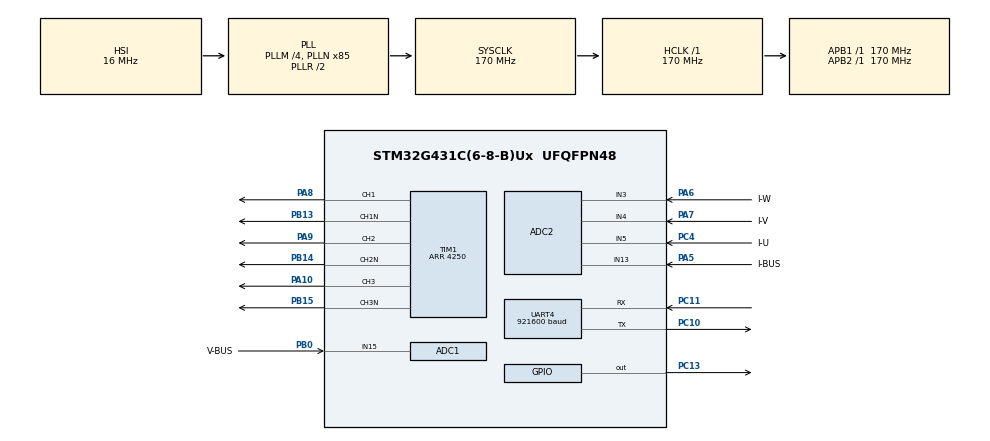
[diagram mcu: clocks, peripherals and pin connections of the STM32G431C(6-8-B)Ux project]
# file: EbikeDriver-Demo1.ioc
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ADC1.Channel-0\#ChannelRegularConversion=ADC_CHANNEL_15
ADC1.ContinuousConvMode=DISABLE
ADC1.DMAContinuousRequests=ENABLE
ADC1.EnableInjectedConversion=DISABLE
ADC1.ExternalTrigConv=ADC_EXTERNALTRIG_T1_TRGO2
ADC1.NbrOfConversionFlag=1
ADC1.OffsetNumber-0\#ChannelRegularConversion=ADC_OFFSET_NONE
ADC1.Overrun=ADC_OVR_DATA_PRESERVED
ADC1.Rank-0\#ChannelRegularConversion=1
ADC1.SamplingTime-0\#ChannelRegularConversion=ADC_SAMPLETIME_12CYCLES_5
ADC1.master=1
ADC2.ClockPrescaler=ADC_CLOCK_SYNC_PCLK_DIV4
ADC2.EnableInjectedConversion=ENABLE
ADC2.EnableRegularConversion=DISABLE
ADC2.ExternalTrigInjecConv=ADC_EXTERNALTRIGINJEC_T1_CC4
ADC2.InjNumberOfConversion=4
ADC2.InjectedChannel-1\#ChannelInjectedConversion=ADC_CHANNEL_13
ADC2.InjectedChannel-2\#ChannelInjectedConversion=ADC_CHANNEL_5
ADC2.InjectedChannel-3\#ChannelInjectedConversion=ADC_CHANNEL_4
ADC2.InjectedChannel-5\#ChannelInjectedConversion=ADC_CHANNEL_3
ADC2.InjectedOffsetNumber-1\#ChannelInjectedConversion=ADC_OFFSET_NONE
ADC2.InjectedOffsetNumber-2\#ChannelInjectedConversion=ADC_OFFSET_NONE
ADC2.InjectedOffsetNumber-3\#ChannelInjectedConversion=ADC_OFFSET_NONE
ADC2.InjectedOffsetNumber-5\#ChannelInjectedConversion=ADC_OFFSET_NONE
ADC2.InjectedRank-1\#ChannelInjectedConversion=1
ADC2.InjectedRank-2\#ChannelInjectedConversion=2
ADC2.InjectedRank-3\#ChannelInjectedConversion=3
ADC2.InjectedRank-5\#ChannelInjectedConversion=4
ADC2.InjectedSamplingTime-1\#ChannelInjectedConversion=ADC_SAMPLETIME_12CYCLES_5
ADC2.InjectedSamplingTime-2\#ChannelInjectedConversion=ADC_SAMPLETIME_12CYCLES_5
ADC2.InjectedSamplingTime-3\#ChannelInjectedConversion=ADC_SAMPLETIME_12CYCLES_5
ADC2.InjectedSamplingTime-5\#ChannelInjectedConversion=ADC_SAMPLETIME_12CYCLES_5
ADC2.Rank1_Channel=ADC_CHANNEL_13
ADC2.Rank2_Channel=ADC_CHANNEL_5
ADC2.Rank3_Channel=ADC_CHANNEL_4
ADC2.Rank4_Channel=ADC_CHANNEL_3
Dma.ADC1.1.Direction=DMA_PERIPH_TO_MEMORY
Dma.ADC1.1.EventEnable=DISABLE
Dma.ADC1.1.Instance=DMA1_Channel2
Dma.ADC1.1.MemDataAlignment=DMA_MDATAALIGN_HALFWORD
Dma.ADC1.1.MemInc=DMA_MINC_ENABLE
Dma.ADC1.1.Mode=DMA_CIRCULAR
Dma.ADC1.1.PeriphDataAlignment=DMA_PDATAALIGN_HALFWORD
Dma.ADC1.1.PeriphInc=DMA_PINC_DISABLE
Dma.ADC1.1.Polarity=HAL_DMAMUX_REQ_GEN_RISING
Dma.ADC1.1.Priority=DMA_PRIORITY_LOW
Dma.ADC1.1.RequestNumber=1
Dma.ADC1.1.SignalID=NONE
Dma.ADC1.1.SyncEnable=DISABLE
Dma.ADC1.1.SyncPolarity=HAL_DMAMUX_SYNC_NO_EVENT
Dma.ADC1.1.SyncRequestNumber=1
Dma.ADC1.1.SyncSignalID=NONE
Dma.Request0=UART4_TX
Dma.Request1=ADC1
Dma.UART4_TX.0.Direction=DMA_MEMORY_TO_PERIPH
Dma.UART4_TX.0.EventEnable=DISABLE
Dma.UART4_TX.0.Instance=DMA1_Channel1
Dma.UART4_TX.0.MemDataAlignment=DMA_MDATAALIGN_BYTE
Dma.UART4_TX.0.MemInc=DMA_MINC_ENABLE
Dma.UART4_TX.0.Mode=DMA_NORMAL
Dma.UART4_TX.0.PeriphDataAlignment=DMA_PDATAALIGN_BYTE
Dma.UART4_TX.0.PeriphInc=DMA_PINC_DISABLE
Dma.UART4_TX.0.Polarity=HAL_DMAMUX_REQ_GEN_RISING
Dma.UART4_TX.0.Priority=DMA_PRIORITY_LOW
Dma.UART4_TX.0.RequestNumber=1
Dma.UART4_TX.0.SignalID=NONE
Dma.UART4_TX.0.SyncEnable=DISABLE
Dma.UART4_TX.0.SyncPolarity=HAL_DMAMUX_SYNC_NO_EVENT
Dma.UART4_TX.0.SyncRequestNumber=1
Dma.UART4_TX.0.SyncSignalID=NONE
Mcu.Family=STM32G4
Mcu.Name=STM32G431C(6-8-B)Ux
Mcu.Package=UFQFPN48
NVIC.ADC1_2_IRQn=true\:0\:0\:false\:false\:true\:true\:true\:true
NVIC.DMA1_Channel1_IRQn=true\:1\:0\:true\:false\:true\:false\:true\:true
NVIC.DMA1_Channel2_IRQn=true\:2\:0\:true\:false\:true\:false\:true\:true
NVIC.PriorityGroup=NVIC_PRIORITYGROUP_4
NVIC.UART4_IRQn=true\:2\:0\:true\:false\:true\:true\:true\:true
PA10.Signal=S_TIM1_CH3
PA13.Mode=Serial_Wire
PA13.Signal=SYS_JTMS-SWDIO
PA14.Mode=Serial_Wire
PA14.Signal=SYS_JTCK-SWCLK
PA5.GPIO_Label=I-BUS
PA5.Mode=IN13-Single-Ended
PA5.Signal=ADC2_IN13
PA6.GPIO_Label=I-W
PA6.Mode=IN3-Single-Ended
PA6.Signal=ADC2_IN3
PA7.GPIO_Label=I-V
PA7.Mode=IN4-Single-Ended
PA7.Signal=ADC2_IN4
PA8.Signal=S_TIM1_CH1
PA9.Signal=S_TIM1_CH2
PB0.GPIO_Label=V-BUS
PB0.Mode=IN15-Single-Ended
PB0.Signal=ADC1_IN15
PB13.Mode=PWM Generation1 CH1 CH1N
PB13.Signal=TIM1_CH1N
PB14.Mode=PWM Generation2 CH2 CH2N
PB14.Signal=TIM1_CH2N
PB15.Mode=PWM Generation3 CH3 CH3N
PB15.Signal=TIM1_CH3N
PC10.Mode=Asynchronous
PC10.Signal=UART4_TX
PC11.Mode=Asynchronous
PC11.Signal=UART4_RX
PC13.Signal=GPIO_Output
PC4.GPIO_Label=I-U
PC4.Mode=IN5-Single-Ended
PC4.Signal=ADC2_IN5
PF0-OSC_IN.Mode=HSE-External-Oscillator
PF0-OSC_IN.Signal=RCC_OSC_IN
PF1-OSC_OUT.Mode=HSE-External-Oscillator
PF1-OSC_OUT.Signal=RCC_OSC_OUT
ProjectManager.HeapSize=0x200
ProjectManager.StackSize=0x400
ProjectManager.TargetToolchain=CMake
RCC.ADC12Freq_Value=170000000
RCC.AHBFreq_Value=170000000
RCC.APB1Freq_Value=170000000
RCC.APB1TimFreq_Value=170000000
RCC.APB2Freq_Value=170000000
RCC.APB2TimFreq_Value=170000000
RCC.CortexFreq_Value=170000000
RCC.EXTERNAL_CLOCK_VALUE=12288000
RCC.HCLKFreq_Value=170000000
RCC.HSE_VALUE=8000000
RCC.HSI48_VALUE=48000000
RCC.HSI_VALUE=16000000
RCC.LSE_VALUE=32768
RCC.PLLM=RCC_PLLM_DIV4
RCC.PLLN=85
RCC.SYSCLKFreq_VALUE=170000000
RCC.SYSCLKSource=RCC_SYSCLKSOURCE_PLLCLK
RCC.USBFreq_Value=170000000
RCC.VCOOutputFreq_Value=340000000
SH.S_TIM1_CH1.0=TIM1_CH1,PWM Generation1 CH1 CH1N
SH.S_TIM1_CH2.0=TIM1_CH2,PWM Generation2 CH2 CH2N
SH.S_TIM1_CH3.0=TIM1_CH3,PWM Generation3 CH3 CH3N
TIM1.Channel-PWM\ Generation1\ CH1\ CH1N=TIM_CHANNEL_1
TIM1.Channel-PWM\ Generation2\ CH2\ CH2N=TIM_CHANNEL_2
TIM1.Channel-PWM\ Generation3\ CH3\ CH3N=TIM_CHANNEL_3
TIM1.Channel-PWM\ Generation4\ No\ Output=TIM_CHANNEL_4
TIM1.CounterMode=TIM_COUNTERMODE_CENTERALIGNED1
TIM1.DeadTime=32
TIM1.OCNPolarity_1=TIM_OCNPOLARITY_LOW
TIM1.OCNPolarity_2=TIM_OCNPOLARITY_LOW
TIM1.OCNPolarity_3=TIM_OCNPOLARITY_LOW
TIM1.OCPolarity_1=TIM_OCPOLARITY_LOW
TIM1.OCPolarity_2=TIM_OCPOLARITY_LOW
TIM1.OCPolarity_3=TIM_OCPOLARITY_LOW
TIM1.PeriodNoDither=4250
TIM1.TIM_MasterOutputTrigger=TIM_TRGO_OC4REF
TIM1.TIM_MasterOutputTrigger2=TIM_TRGO2_OC4REF
UART4.BaudRate=921600
UART4.Mode=MODE_TX
VP_SYS_VS_DBSignals.Mode=DisableDeadBatterySignals
VP_TIM1_VS_no_output4.Mode=PWM Generation4 No Output
board=custom

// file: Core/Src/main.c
/* USER CODE BEGIN Header */
/**
  ******************************************************************************
  * @file           : main.c
  * @brief          : Main program body
  ******************************************************************************
  * @attention
  *
  * Copyright (c) 2026 STMicroelectronics.
  * All rights reserved.
  *
  * This software is licensed under terms that can be found in the LICENSE file
  * in the root directory of this software component.
  * If no LICENSE file comes with this software, it is provided AS-IS.
  *
  ******************************************************************************
  */
/* USER CODE END Header */
#include "main.h"

ADC_HandleTypeDef hadc1;
ADC_HandleTypeDef hadc2;
DMA_HandleTypeDef hdma_adc1;

TIM_HandleTypeDef htim1;

UART_HandleTypeDef huart4;
DMA_HandleTypeDef hdma_uart4_tx;

void SystemClock_Config(void);
static void MX_GPIO_Init(void);
static void MX_DMA_Init(void);
static void MX_ADC2_Init(void);
static void MX_TIM1_Init(void);
static void MX_UART4_Init(void);
static void MX_ADC1_Init(void);

int main(void)
{

  /* MCU Configuration--------------------------------------------------------*/

  /* Reset of all peripherals, Initializes the Flash interface and the Systick. */
  HAL_Init();

  /* Configure the system clock */
  SystemClock_Config();

  /* Initialize all configured peripherals */
  MX_GPIO_Init();
  MX_DMA_Init();
  MX_ADC2_Init();
  MX_TIM1_Init();
  MX_UART4_Init();
  MX_ADC1_Init();
  /* USER CODE BEGIN 2 */
  HAL_Delay(500);
  User_Init();
  /* USER CODE END 2 */

  /* Infinite loop */
  while (1)
  {

    /* USER CODE BEGIN 3 */
    User_Loop();
  }
  /* USER CODE END 3 */
}

void SystemClock_Config(void)
{
  RCC_OscInitTypeDef RCC_OscInitStruct = {0};
  RCC_ClkInitTypeDef RCC_ClkInitStruct = {0};

  /** Configure the main internal regulator output voltage
  */
  HAL_PWREx_ControlVoltageScaling(PWR_REGULATOR_VOLTAGE_SCALE1_BOOST);

  /** Initializes the RCC Oscillators according to the specified parameters
  * in the RCC_OscInitTypeDef structure.
  */
  RCC_OscInitStruct.OscillatorType = RCC_OSCILLATORTYPE_HSI;
  RCC_OscInitStruct.HSIState = RCC_HSI_ON;
  RCC_OscInitStruct.HSICalibrationValue = RCC_HSICALIBRATION_DEFAULT;
  RCC_OscInitStruct.PLL.PLLState = RCC_PLL_ON;
  RCC_OscInitStruct.PLL.PLLSource = RCC_PLLSOURCE_HSI;
  RCC_OscInitStruct.PLL.PLLM = RCC_PLLM_DIV4;
  RCC_OscInitStruct.PLL.PLLN = 85;
  RCC_OscInitStruct.PLL.PLLP = RCC_PLLP_DIV2;
  RCC_OscInitStruct.PLL.PLLQ = RCC_PLLQ_DIV2;
  RCC_OscInitStruct.PLL.PLLR = RCC_PLLR_DIV2;
  if (HAL_RCC_OscConfig(&RCC_OscInitStruct) != HAL_OK)
  {
    Error_Handler();
  }

  /** Initializes the CPU, AHB and APB buses clocks
  */
  RCC_ClkInitStruct.ClockType = RCC_CLOCKTYPE_HCLK|RCC_CLOCKTYPE_SYSCLK
                              |RCC_CLOCKTYPE_PCLK1|RCC_CLOCKTYPE_PCLK2;
  RCC_ClkInitStruct.SYSCLKSource = RCC_SYSCLKSOURCE_PLLCLK;
  RCC_ClkInitStruct.AHBCLKDivider = RCC_SYSCLK_DIV1;
  RCC_ClkInitStruct.APB1CLKDivider = RCC_HCLK_DIV1;
  RCC_ClkInitStruct.APB2CLKDivider = RCC_HCLK_DIV1;

  if (HAL_RCC_ClockConfig(&RCC_ClkInitStruct, FLASH_LATENCY_4) != HAL_OK)
  {
    Error_Handler();
  }
}

static void MX_ADC1_Init(void)
{

  ADC_MultiModeTypeDef multimode = {0};
  ADC_ChannelConfTypeDef sConfig = {0};

  /** Common config
  */
  hadc1.Instance = ADC1;
  hadc1.Init.ClockPrescaler = ADC_CLOCK_SYNC_PCLK_DIV4;
  hadc1.Init.Resolution = ADC_RESOLUTION_12B;
  hadc1.Init.DataAlign = ADC_DATAALIGN_RIGHT;
  hadc1.Init.GainCompensation = 0;
  hadc1.Init.ScanConvMode = ADC_SCAN_DISABLE;
  hadc1.Init.EOCSelection = ADC_EOC_SINGLE_CONV;
  hadc1.Init.LowPowerAutoWait = DISABLE;
  hadc1.Init.ContinuousConvMode = DISABLE;
  hadc1.Init.NbrOfConversion = 1;
  hadc1.Init.DiscontinuousConvMode = DISABLE;
  hadc1.Init.ExternalTrigConv = ADC_EXTERNALTRIG_T1_TRGO2;
  hadc1.Init.ExternalTrigConvEdge = ADC_EXTERNALTRIGCONVEDGE_RISING;
  hadc1.Init.DMAContinuousRequests = ENABLE;
  hadc1.Init.Overrun = ADC_OVR_DATA_PRESERVED;
  hadc1.Init.OversamplingMode = DISABLE;
  if (HAL_ADC_Init(&hadc1) != HAL_OK)
  {
    Error_Handler();
  }

  /** Configure the ADC multi-mode
  */
  multimode.Mode = ADC_MODE_INDEPENDENT;
  if (HAL_ADCEx_MultiModeConfigChannel(&hadc1, &multimode) != HAL_OK)
  {
    Error_Handler();
  }

  /** Configure Regular Channel
  */
  sConfig.Channel = ADC_CHANNEL_15;
  sConfig.Rank = ADC_REGULAR_RANK_1;
  sConfig.SamplingTime = ADC_SAMPLETIME_12CYCLES_5;
  sConfig.SingleDiff = ADC_SINGLE_ENDED;
  sConfig.OffsetNumber = ADC_OFFSET_NONE;
  sConfig.Offset = 0;
  if (HAL_ADC_ConfigChannel(&hadc1, &sConfig) != HAL_OK)
  {
    Error_Handler();
  }

}

static void MX_ADC2_Init(void)
{

  ADC_InjectionConfTypeDef sConfigInjected = {0};

  /** Common config
  */
  hadc2.Instance = ADC2;
  hadc2.Init.ClockPrescaler = ADC_CLOCK_SYNC_PCLK_DIV4;
  hadc2.Init.Resolution = ADC_RESOLUTION_12B;
  hadc2.Init.DataAlign = ADC_DATAALIGN_RIGHT;
  hadc2.Init.GainCompensation = 0;
  hadc2.Init.ScanConvMode = ADC_SCAN_ENABLE;
  hadc2.Init.EOCSelection = ADC_EOC_SINGLE_CONV;
  hadc2.Init.LowPowerAutoWait = DISABLE;
  hadc2.Init.ContinuousConvMode = DISABLE;
  hadc2.Init.NbrOfConversion = 1;
  hadc2.Init.DiscontinuousConvMode = DISABLE;
  hadc2.Init.DMAContinuousRequests = DISABLE;
  hadc2.Init.Overrun = ADC_OVR_DATA_PRESERVED;
  hadc2.Init.OversamplingMode = DISABLE;
  if (HAL_ADC_Init(&hadc2) != HAL_OK)
  {
    Error_Handler();
  }

  /** Configure Injected Channel
  */
  sConfigInjected.InjectedChannel = ADC_CHANNEL_13;
  sConfigInjected.InjectedRank = ADC_INJECTED_RANK_1;
  sConfigInjected.InjectedSamplingTime = ADC_SAMPLETIME_12CYCLES_5;
  sConfigInjected.InjectedSingleDiff = ADC_SINGLE_ENDED;
  sConfigInjected.InjectedOffsetNumber = ADC_OFFSET_NONE;
  sConfigInjected.InjectedOffset = 0;
  sConfigInjected.InjectedNbrOfConversion = 4;
  sConfigInjected.InjectedDiscontinuousConvMode = DISABLE;
  sConfigInjected.AutoInjectedConv = DISABLE;
  sConfigInjected.QueueInjectedContext = DISABLE;
  sConfigInjected.ExternalTrigInjecConv = ADC_EXTERNALTRIGINJEC_T1_CC4;
  sConfigInjected.ExternalTrigInjecConvEdge = ADC_EXTERNALTRIGINJECCONV_EDGE_RISING;
  sConfigInjected.InjecOversamplingMode = DISABLE;
  if (HAL_ADCEx_InjectedConfigChannel(&hadc2, &sConfigInjected) != HAL_OK)
  {
    Error_Handler();
  }

  /** Configure Injected Channel
  */
  sConfigInjected.InjectedChannel = ADC_CHANNEL_5;
  sConfigInjected.InjectedRank = ADC_INJECTED_RANK_2;
  if (HAL_ADCEx_InjectedConfigChannel(&hadc2, &sConfigInjected) != HAL_OK)
  {
    Error_Handler();
  }

  /** Configure Injected Channel
  */
  sConfigInjected.InjectedChannel = ADC_CHANNEL_4;
  sConfigInjected.InjectedRank = ADC_INJECTED_RANK_3;
  if (HAL_ADCEx_InjectedConfigChannel(&hadc2, &sConfigInjected) != HAL_OK)
  {
    Error_Handler();
  }

  /** Configure Injected Channel
  */
  sConfigInjected.InjectedChannel = ADC_CHANNEL_3;
  sConfigInjected.InjectedRank = ADC_INJECTED_RANK_4;
  if (HAL_ADCEx_InjectedConfigChannel(&hadc2, &sConfigInjected) != HAL_OK)
  {
    Error_Handler();
  }

}

static void MX_TIM1_Init(void)
{

  TIM_MasterConfigTypeDef sMasterConfig = {0};
  TIM_OC_InitTypeDef sConfigOC = {0};
  TIM_BreakDeadTimeConfigTypeDef sBreakDeadTimeConfig = {0};

  htim1.Instance = TIM1;
  htim1.Init.Prescaler = 0;
  htim1.Init.CounterMode = TIM_COUNTERMODE_CENTERALIGNED1;
  htim1.Init.Period = 4250;
  htim1.Init.ClockDivision = TIM_CLOCKDIVISION_DIV1;
  htim1.Init.RepetitionCounter = 0;
  htim1.Init.AutoReloadPreload = TIM_AUTORELOAD_PRELOAD_DISABLE;
  if (HAL_TIM_PWM_Init(&htim1) != HAL_OK)
  {
    Error_Handler();
  }
  sMasterConfig.MasterOutputTrigger = TIM_TRGO_OC4REF;
  sMasterConfig.MasterOutputTrigger2 = TIM_TRGO2_OC4REF;
  sMasterConfig.MasterSlaveMode = TIM_MASTERSLAVEMODE_DISABLE;
  if (HAL_TIMEx_MasterConfigSynchronization(&htim1, &sMasterConfig) != HAL_OK)
  {
    Error_Handler();
  }
  sConfigOC.OCMode = TIM_OCMODE_PWM1;
  sConfigOC.Pulse = 0;
  sConfigOC.OCPolarity = TIM_OCPOLARITY_LOW;
  sConfigOC.OCNPolarity = TIM_OCNPOLARITY_LOW;
  sConfigOC.OCFastMode = TIM_OCFAST_DISABLE;
  sConfigOC.OCIdleState = TIM_OCIDLESTATE_RESET;
  sConfigOC.OCNIdleState = TIM_OCNIDLESTATE_RESET;
  if (HAL_TIM_PWM_ConfigChannel(&htim1, &sConfigOC, TIM_CHANNEL_1) != HAL_OK)
  {
    Error_Handler();
  }
  if (HAL_TIM_PWM_ConfigChannel(&htim1, &sConfigOC, TIM_CHANNEL_2) != HAL_OK)
  {
    Error_Handler();
  }
  if (HAL_TIM_PWM_ConfigChannel(&htim1, &sConfigOC, TIM_CHANNEL_3) != HAL_OK)
  {
    Error_Handler();
  }
  sConfigOC.OCPolarity = TIM_OCPOLARITY_HIGH;
  sConfigOC.OCNPolarity = TIM_OCNPOLARITY_HIGH;
  if (HAL_TIM_PWM_ConfigChannel(&htim1, &sConfigOC, TIM_CHANNEL_4) != HAL_OK)
  {
    Error_Handler();
  }
  sBreakDeadTimeConfig.OffStateRunMode = TIM_OSSR_DISABLE;
  sBreakDeadTimeConfig.OffStateIDLEMode = TIM_OSSI_DISABLE;
  sBreakDeadTimeConfig.LockLevel = TIM_LOCKLEVEL_OFF;
  sBreakDeadTimeConfig.DeadTime = 32;
  sBreakDeadTimeConfig.BreakState = TIM_BREAK_DISABLE;
  sBreakDeadTimeConfig.BreakPolarity = TIM_BREAKPOLARITY_HIGH;
  sBreakDeadTimeConfig.BreakFilter = 0;
  sBreakDeadTimeConfig.BreakAFMode = TIM_BREAK_AFMODE_INPUT;
  sBreakDeadTimeConfig.Break2State = TIM_BREAK2_DISABLE;
  sBreakDeadTimeConfig.Break2Polarity = TIM_BREAK2POLARITY_HIGH;
  sBreakDeadTimeConfig.Break2Filter = 0;
  sBreakDeadTimeConfig.Break2AFMode = TIM_BREAK_AFMODE_INPUT;
  sBreakDeadTimeConfig.AutomaticOutput = TIM_AUTOMATICOUTPUT_DISABLE;
  if (HAL_TIMEx_ConfigBreakDeadTime(&htim1, &sBreakDeadTimeConfig) != HAL_OK)
  {
    Error_Handler();
  }
  HAL_TIM_MspPostInit(&htim1);

}

static void MX_UART4_Init(void)
{

  huart4.Instance = UART4;
  huart4.Init.BaudRate = 921600;
  huart4.Init.WordLength = UART_WORDLENGTH_8B;
  huart4.Init.StopBits = UART_STOPBITS_1;
  huart4.Init.Parity = UART_PARITY_NONE;
  huart4.Init.Mode = UART_MODE_TX;
  huart4.Init.HwFlowCtl = UART_HWCONTROL_NONE;
  huart4.Init.OverSampling = UART_OVERSAMPLING_16;
  huart4.Init.OneBitSampling = UART_ONE_BIT_SAMPLE_DISABLE;
  huart4.Init.ClockPrescaler = UART_PRESCALER_DIV1;
  huart4.AdvancedInit.AdvFeatureInit = UART_ADVFEATURE_NO_INIT;
  if (HAL_UART_Init(&huart4) != HAL_OK)
  {
    Error_Handler();
  }
  if (HAL_UARTEx_SetTxFifoThreshold(&huart4, UART_TXFIFO_THRESHOLD_1_8) != HAL_OK)
  {
    Error_Handler();
  }
  if (HAL_UARTEx_SetRxFifoThreshold(&huart4, UART_RXFIFO_THRESHOLD_1_8) != HAL_OK)
  {
    Error_Handler();
  }
  if (HAL_UARTEx_DisableFifoMode(&huart4) != HAL_OK)
  {
    Error_Handler();
  }

}

static void MX_DMA_Init(void)
{

  /* DMA controller clock enable */
  __HAL_RCC_DMAMUX1_CLK_ENABLE();
  __HAL_RCC_DMA1_CLK_ENABLE();

  /* DMA interrupt init */
  /* DMA1_Channel1_IRQn interrupt configuration */
  HAL_NVIC_SetPriority(DMA1_Channel1_IRQn, 1, 0);
  HAL_NVIC_EnableIRQ(DMA1_Channel1_IRQn);
  /* DMA1_Channel2_IRQn interrupt configuration */
  HAL_NVIC_SetPriority(DMA1_Channel2_IRQn, 2, 0);
  HAL_NVIC_EnableIRQ(DMA1_Channel2_IRQn);

}

static void MX_GPIO_Init(void)
{
  GPIO_InitTypeDef GPIO_InitStruct = {0};

  /* GPIO Ports Clock Enable */
  __HAL_RCC_GPIOC_CLK_ENABLE();
  __HAL_RCC_GPIOF_CLK_ENABLE();
  __HAL_RCC_GPIOA_CLK_ENABLE();
  __HAL_RCC_GPIOB_CLK_ENABLE();

  /*Configure GPIO pin Output Level */
  HAL_GPIO_WritePin(GPIOC, GPIO_PIN_13, GPIO_PIN_RESET);

  /*Configure GPIO pin : PC13 */
  GPIO_InitStruct.Pin = GPIO_PIN_13;
  GPIO_InitStruct.Mode = GPIO_MODE_OUTPUT_PP;
  GPIO_InitStruct.Pull = GPIO_NOPULL;
  GPIO_InitStruct.Speed = GPIO_SPEED_FREQ_LOW;
  HAL_GPIO_Init(GPIOC, &GPIO_InitStruct);

}

void Error_Handler(void)
{
  __disable_irq();
  while (1)
  {
  }
}
